VERSION ""

NS_ :

BS_:

BU_:
VAL_TABLE_ Register_FOB 0 "Normal" 1 "Success" 2 "Failure" 3 "Lock" ;
VAL_TABLE_ Detect_FOB 0 "Default" 1 "On" 2 "Off" 3 "Fail" ;
VAL_TABLE_ Request_FOB_ID 0 "Default" 1 "On" 2 "Off" 3 "Fail" ;
VAL_TABLE_ Door_Status 0 "Default" 1 "Lock" 2 "Unlock" ;
VAL_TABLE_ Air_Conditioner_Status 0 "Default" 1 "On" 2 "Off" 3 "Fail" ;
VAL_TABLE_ Machine_Status 0 "Default" 1 "EngineOn" 2 "EngineOff" 3 "KeyOn" ;
VAL_TABLE_ Lamp_Status 0 "Default" 1 "On" 2 "Off" 3 "Fail" ;
VAL_TABLE_ Door_Release 0 "Default" 3 "Fail" 2 "ReleaseOn" 3 "ReleaseOff" ;
VAL_TABLE_ Door_Status 0 "Unlock" 1 "Lock" 2 "Release_Unlock" 3 "Release_Lock" ;
VAL_TABLE_ Air_Conditioner_Status 0 "Default" 3 "Failed" 1 "On" 2 "Off" ;
VAL_TABLE_ Lamp_Status 0 "Default" 3 "Failed" 1 "On" 2 "Off" ;
VAL_TABLE_ Pre_Heating_Status 0 "Default" 3 "Failed" 1 "On" 2 "Off" ;
VAL_TABLE_ FOB_Registration_Status_Feedback 0 "Default" 1 "NoDetect" 2 "Detected" 3 "NA" ;
VAL_TABLE_ Warn_NoFob 0 "Normal" 1 "On" 2 "BlinkFast" 3 "BlinkSlow" ;
VAL_TABLE_ Warn_LowBat 0 "Normal" 1 "On" 2 "BlinkFast" 3 "BlinkSlow" ;
VAL_TABLE_ Warn_Immo 0 "Normal" 1 "On" 2 "BlinkFast" 3 "BlinkSlow" ;

BO_ 2566842624 ECU_LFC: 8 Vector__XXX
 SG_ EngineTripFuel : 0|32@1+ (0.5,0) [0|2105540607.5] "l" Vector__XXX
 SG_ EngineTotalFuelUsed : 32|32@1+ (0.5,0) [0|2105540607.5] "l" Vector__XXX

BO_ 2566719744 ECU_HRLFC: 8 Vector__XXX
 SG_ EngineTripFuel : 0|32@1+ (0.001,0) [0|4211081.215] "l" Vector__XXX
 SG_ EngineTotalFuelUsed : 32|32@1+ (0.001,0) [0|4211081.215] "l" Vector__XXX

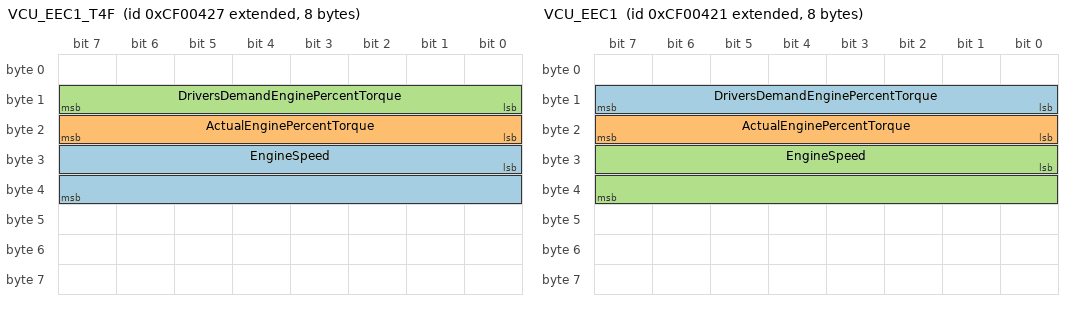
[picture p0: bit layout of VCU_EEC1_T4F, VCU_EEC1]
BO_ 2364539943 VCU_EEC1_T4F: 8 Vector__XXX
 SG_ EngineSpeed : 24|16@1+ (0.125,0) [0|8031.875] "rpm" Vector__XXX
 SG_ ActualEnginePercentTorque : 16|8@1+ (1,-125) [-125|125] "%" Vector__XXX
 SG_ DriversDemandEnginePercentTorque : 8|8@1+ (1,-125) [-125|125] "%" Vector__XXX

BO_ 2364539937 VCU_EEC1: 8 Vector__XXX
 SG_ DriversDemandEnginePercentTorque : 8|8@1+ (1,-125) [-125|125] "%" Vector__XXX
 SG_ ActualEnginePercentTorque : 16|8@1+ (1,-125) [-125|125] "%" Vector__XXX
 SG_ EngineSpeed : 24|16@1+ (0.125,0) [0|8031.875] "rpm" Vector__XXX

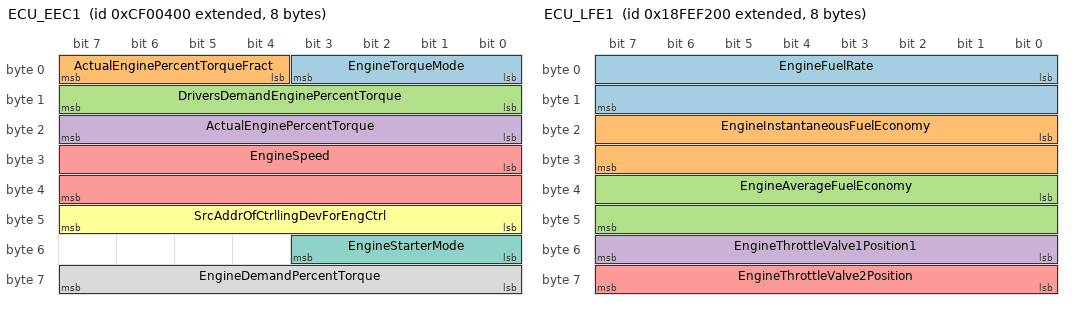
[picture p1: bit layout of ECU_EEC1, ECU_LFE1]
BO_ 2364539904 ECU_EEC1: 8 Vector__XXX
 SG_ EngineTorqueMode : 0|4@1+ (1,0) [0|15] "" Vector__XXX
 SG_ ActualEnginePercentTorqueFract : 4|4@1+ (0.125,0) [0|0.875] "%" Vector__XXX
 SG_ DriversDemandEnginePercentTorque : 8|8@1+ (1,-125) [-125|125] "%" Vector__XXX
 SG_ ActualEnginePercentTorque : 16|8@1+ (1,-125) [-125|125] "%" Vector__XXX
 SG_ EngineSpeed : 24|16@1+ (0.125,0) [0|8031.875] "rpm" Vector__XXX
 SG_ SrcAddrOfCtrllingDevForEngCtrl : 40|8@1+ (1,0) [0|255] "" Vector__XXX
 SG_ EngineStarterMode : 48|4@1+ (1,0) [0|15] "" Vector__XXX
 SG_ EngineDemandPercentTorque : 56|8@1+ (1,-125) [-125|125] "%" Vector__XXX

BO_ 2566841600 ECU_HOURS: 8 Vector__XXX
 SG_ EngineTotalHoursOfOperation : 0|32@1+ (0.05,0) [0|210554060.75] "hr" Vector__XXX
 SG_ EngineTotalRevolutions : 32|32@1+ (1000,0) [0|4211081215000] "" Vector__XXX

BO_ 2181014528 PHM_Time: 8 Vector__XXX
 SG_ TimeStamp : 32|32@1+ (1,0) [0|4294967295] "" Vector__XXX
 SG_ EngineTotalHoursOfOperation : 0|32@1+ (0.05,0) [0|210554060.75] "hr" Vector__XXX

BO_ 2566844928 ECU_LFE1: 8 Vector__XXX
 SG_ EngineFuelRate : 0|16@1+ (0.05,0) [0|3212.75] "l/h" Vector__XXX
 SG_ EngineInstantaneousFuelEconomy : 16|16@1+ (0.001953125,0) [0|125.498046875] "km/l" Vector__XXX
 SG_ EngineAverageFuelEconomy    : 32|16@1+ (0.001953125,0) [0|125.498046875] "km/l" Vector__XXX
 SG_ EngineThrottleValve1Position1 : 48|8@1+ (0.4,0) [0|100] "%" Vector__XXX
 SG_ EngineThrottleValve2Position : 56|8@1+ (0.4,0) [0|100] "%" Vector__XXX

BO_ 2566839296 ECU_IO: 8 Vector__XXX
 SG_ EngineTotalIdleFuelUsed : 0|32@1+ (0.5,0) [0|2105540607.5] "l" Vector__XXX
 SG_ EngineTotalIdleHours : 32|32@1+ (0.05,0) [0|210554060.75] "hr" Vector__XXX

BO_ 2566897959 VCU3_Proprietary_A1: 8 Vector__XXX
 SG_ FuelLevel : 0|8@1+ (1,0) [0|100] "%" Vector__XXX
 SG_ VCUCONFIGLEVEL : 56|8@1+ (1,0) [0|255] "" Vector__XXX
 SG_ WasherTankLevel : 48|2@1+ (1,0) [0|3] "" Vector__XXX
 SG_ BodyStateLamp : 40|3@1+ (1,0) [0|7] "" Vector__XXX
 SG_ EngineAirFilterClogged : 38|2@1+ (1,0) [0|3] "" Vector__XXX
 SG_ LampFailure : 36|2@1+ (1,0) [0|3] "" Vector__XXX
 SG_ LubricationSystemLamp : 34|2@1+ (1,0) [0|3] "" Vector__XXX
 SG_ EngineCoolantLevelLamp : 32|2@1+ (1,0) [0|3] "" Vector__XXX
 SG_ GeneralFaultLamp : 30|2@1+ (1,0) [0|3] "" Vector__XXX
 SG_ HydraulicSystemLamp : 28|2@1+ (1,0) [0|3] "" Vector__XXX
 SG_ EmergencySteeringLamp : 26|2@1+ (1,0) [0|3] "" Vector__XXX
 SG_ BrakeFaultLamp : 24|2@1+ (1,0) [0|3] "" Vector__XXX
 SG_ RoofBeaconLight : 22|2@1+ (1,0) [0|3] "" Vector__XXX
 SG_ SeatBeltLamp : 20|2@1+ (1,0) [0|3] "" Vector__XXX
 SG_ RearMirrorArmWorkLights : 18|2@1+ (1,0) [0|3] "" Vector__XXX
 SG_ FrontMirrorArmWorkLights : 16|2@1+ (1,0) [0|3] "" Vector__XXX
 SG_ CabinRoofWorkLights : 14|2@1+ (1,0) [0|3] "" Vector__XXX
 SG_ DirectionLight : 12|2@1+ (1,0) [0|3] "" Vector__XXX
 SG_ ParkMainLightStatus : 8|4@1+ (1,0) [0|15] "" Vector__XXX

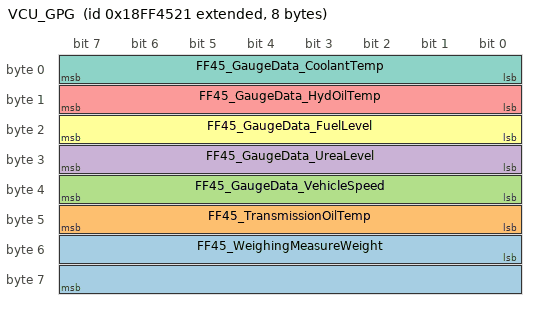
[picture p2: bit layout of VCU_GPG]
BO_ 2566866209 VCU_GPG: 8 Vector__XXX
 SG_ FF45_WeighingMeasureWeight : 48|16@1+ (1,-32127) [-32127|32127] "Kg" Vector__XXX
 SG_ FF45_TransmissionOilTemp : 40|8@1+ (1,0) [0|255] "" Vector__XXX
 SG_ FF45_GaugeData_VehicleSpeed : 32|8@1+ (1,0) [0|255] "km/h" Vector__XXX
 SG_ FF45_GaugeData_UreaLevel : 24|8@1+ (1,0) [0|255] "%" Vector__XXX
 SG_ FF45_GaugeData_HydOilTemp : 8|8@1+ (1,0) [0|255] "%" Vector__XXX
 SG_ FF45_GaugeData_FuelLevel : 16|8@1+ (1,0) [0|255] "%" Vector__XXX
 SG_ FF45_GaugeData_CoolantTemp : 0|8@1+ (1,0) [0|255] "%" Vector__XXX
